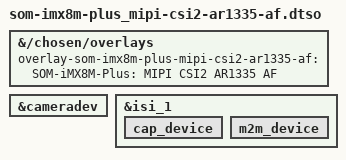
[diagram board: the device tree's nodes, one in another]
#include "overlay.h"

&{/chosen/overlays} {
	overlay-som-imx8m-plus-mipi-csi2-ar1335-af = "SOM-iMX8M-Plus: MIPI CSI2 AR1335 AF";
};

#include "som-imx8m-plus_mipi-csi2.dtsi"

&cameradev {
	status = "okay";
};

&isi_1 {
	status = "okay";

	cap_device {
		status = "okay";
	};

	m2m_device {
		status = "okay";
	};
};
